# SAM9X60 device description
Architecture: ARM926EJS; Family: SAM9; Series: SAM9X
Registers are 32-bit, read-write, no defined reset value unless marked. A register's access mark holds for its fields unless they carry their own. Offsets are from the block's base; [hi:lo] are bit positions; {n}, {i} and the like mark numbered series; 'fields as' and 'values as' point back to an identical list.

## GPBR — General Purpose Backup Registers
Instances: GPBR 0xFFFFFE60
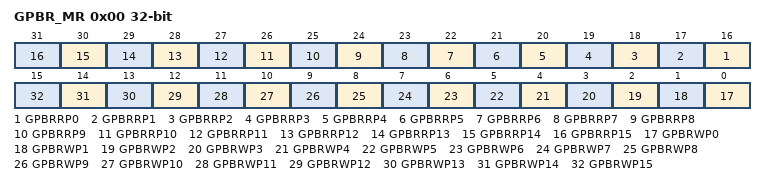
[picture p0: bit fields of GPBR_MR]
0x00 GPBR_MR — GPBR Mode Register
  [n+16] GPBRRP{n} (n=0..15) — GPBRx Read Protection
  [n] GPBRWP{n} (n=0..15) — GPBRx Write Protection
0x04 GPBR_FCLR — GPBR Full Clear Register
  [0] FCLR — Full Clear Enable
{0x8+4i} SYS_GPBR[{i}] (i=0..7) — General Purpose Backup Register
  [31:0] GPBR_VALUE — Value of SYS_GPBR x

## PIT — Periodic Interval Timer
Instances: PIT 0xFFFFFE40
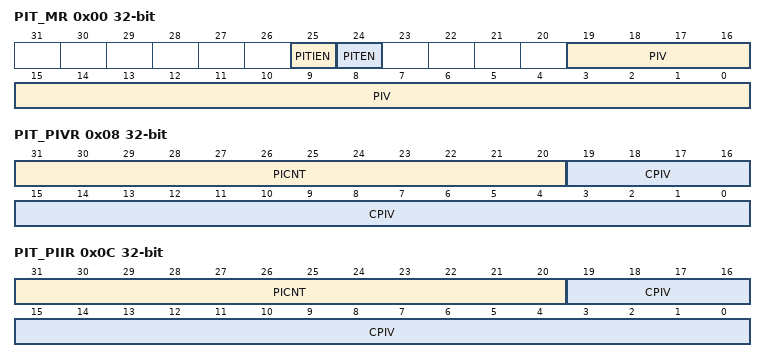
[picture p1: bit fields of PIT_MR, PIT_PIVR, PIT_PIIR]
0x00 PIT_MR — Mode Register
  [25] PITIEN — Periodic Interval Timer Interrupt Enable
  [24] PITEN — Period Interval Timer Enabled
  [19:0] PIV — Periodic Interval Value
0x04 PIT_SR ro — Status Register
  [0] PITS — Periodic Interval Timer Status
0x08 PIT_PIVR ro — Periodic Interval Value Register
  [31:20] PICNT — Periodic Interval Counter
  [19:0] CPIV — Current Periodic Interval Value
0x0C PIT_PIIR ro — Periodic Interval Image Register
  fields as PIT_PIVR

## PIT64B — Periodic Interval Timer 64-bit
Instances: PIT64B 0xF0028000
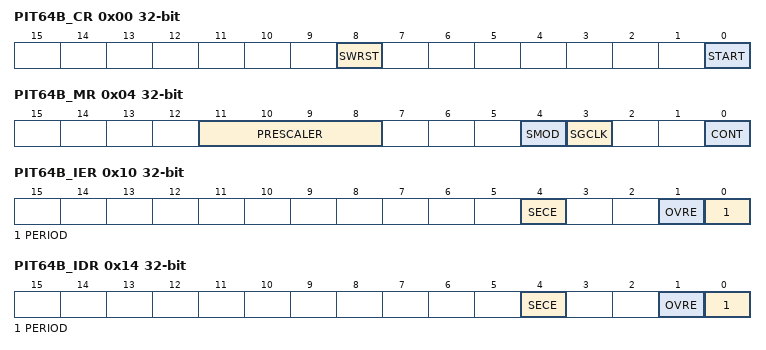
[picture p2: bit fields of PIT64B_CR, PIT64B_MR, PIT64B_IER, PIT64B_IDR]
0x00 PIT64B_CR wo — Control Register
  [8] SWRST — Software Reset
  [0] START — Start Timer
0x04 PIT64B_MR — Mode Register
  [11:8] PRESCALER — Prescaler Period
  [4] SMOD — Start Mode
  [3] SGCLK — Generic Clock Selection Enable
  [0] CONT — Continuous Mode
0x08 PIT64B_LSBPR — LSB Period Register
  [31:0] LSBPERIOD — 32 LSB of the Timer Period
0x0C PIT64B_MSBPR — MSB Period Register
  [31:0] MSBPERIOD — 32 MSB of the Timer Period
0x10 PIT64B_IER wo — Interrupt Enable Register
  [4] SECE — Safety and/or Security Report Interrupt Enable
  [1] OVRE — Overrun Error Interrupt Enable
  [0] PERIOD — Elapsed Timer Period Interrupt Enable
0x14 PIT64B_IDR wo — Interrupt Disable Register
  [4] SECE — Safety and/or Security Report Interrupt Disable
  [1] OVRE — Overrun Error Interrupt Disable
  [0] PERIOD — Elapsed Timer Period Interrupt Disable
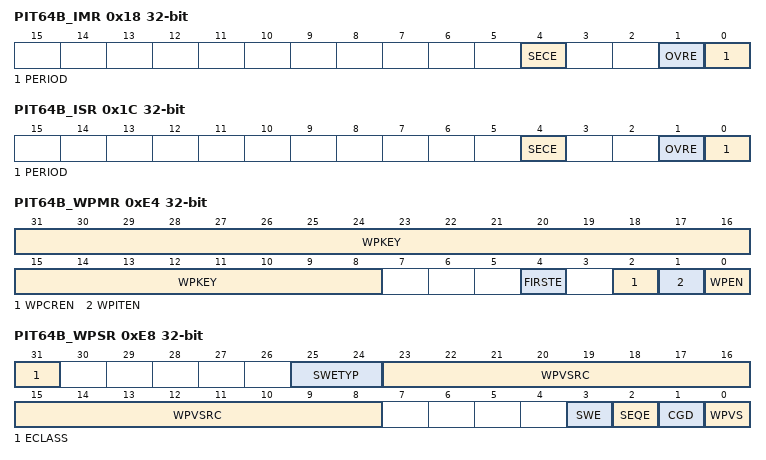
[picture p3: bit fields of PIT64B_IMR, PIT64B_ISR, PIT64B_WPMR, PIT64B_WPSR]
0x18 PIT64B_IMR ro — Interrupt Mask Register
  [4] SECE — Safety and/or Security Report Interrupt Mask
  [1] OVRE — Overrun Error Interrupt Mask
  [0] PERIOD — Elapsed Timer Period Interrupt Mask
0x1C PIT64B_ISR ro — Interrupt Status Register
  [4] SECE — Safety/Security Report (cleared on read)
  [1] OVRE — Overrun Error (cleared on read)
  [0] PERIOD — Elapsed Timer Period Status Flag (cleared on read)
0x20 PIT64B_TLSBR ro — Timer LSB Current Value Register
  [31:0] LSBTIMER — Current 32 LSB of the Timer
0x24 PIT64B_TMSBR ro — Timer MSB Current Value Register
  [31:0] MSBTIMER — Current 32 MSB of the Timer
0xE4 PIT64B_WPMR — Write Protection Mode Register
  [31:8] WPKEY — Write Protection Key
    0x504954=PASSWD (Writing any other value in this field aborts the write operation of the WPCREN, WPITEN and WPEN bits. Always reads as 0.)
  [4] FIRSTE — First Error Report Enable
  [2] WPCREN — Write Protection Control Enable
  [1] WPITEN — Write Protection Interruption Enable
  [0] WPEN — Write Protection Enable
0xE8 PIT64B_WPSR ro — Write Protection Status Register
  [31] ECLASS — Software Error Class (cleared on read)
    0=WARNING (An abnormal access that does not affect system functionality.); 1=ERROR (A write access is performed into PIT64B_MR, PIT64B_LSBR, PIT64B_MSBR while the PIT64B is running.)
  [25:24] SWETYP — Software Error Type (cleared on read)
    0=READ_WO (A write-only register has been read (warning).); 1=WRITE_RO (A write access has been performed on a read-only register (Warning).); 2=UNDEF_RW (Access to an undefined address (warning).); 3=WEIRD_ACTION (A write access is performed into PIT64B_MR, PIT64B_LSBR, PIT64B_MSBR while the PIT64B is running (abnormal).)
  [23:8] WPVSRC — Write Protection Violation Source
  [3] SWE — Software Control Error (cleared on read)
  [2] SEQE — Internal Sequencer Error (cleared on read)
  [1] CGD — Clock Glitch Detected (cleared on read)
  [0] WPVS — Write Protection Violation Status (cleared on read)
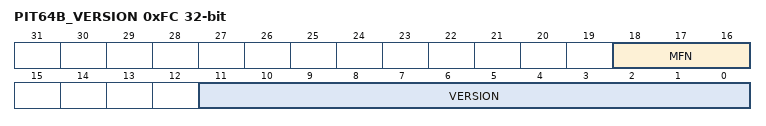
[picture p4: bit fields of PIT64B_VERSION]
0xFC PIT64B_VERSION ro — Version Register
  [18:16] MFN — Metal Fix Number
  [11:0] VERSION — Hardware Module Version
